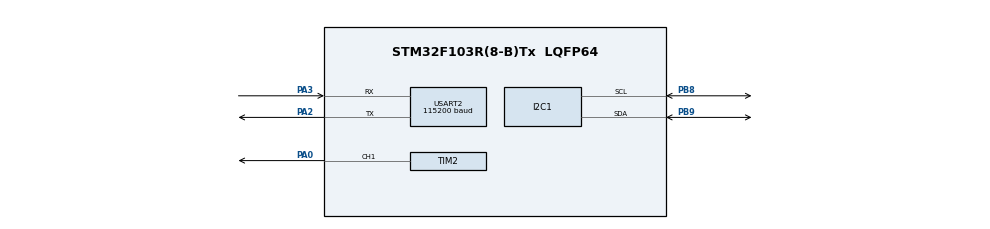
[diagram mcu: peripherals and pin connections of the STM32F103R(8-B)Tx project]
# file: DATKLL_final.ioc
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Dma.Request0=TIM2_CH1
Dma.TIM2_CH1.0.Direction=DMA_MEMORY_TO_PERIPH
Dma.TIM2_CH1.0.Instance=DMA1_Channel5
Dma.TIM2_CH1.0.MemDataAlignment=DMA_MDATAALIGN_HALFWORD
Dma.TIM2_CH1.0.MemInc=DMA_MINC_ENABLE
Dma.TIM2_CH1.0.Mode=DMA_NORMAL
Dma.TIM2_CH1.0.PeriphDataAlignment=DMA_PDATAALIGN_HALFWORD
Dma.TIM2_CH1.0.PeriphInc=DMA_PINC_DISABLE
Dma.TIM2_CH1.0.Priority=DMA_PRIORITY_VERY_HIGH
Mcu.Family=STM32F1
Mcu.Name=STM32F103R(8-B)Tx
Mcu.Package=LQFP64
NVIC.DMA1_Channel5_IRQn=true\:0\:0\:false\:false\:true\:false\:true
NVIC.PriorityGroup=NVIC_PRIORITYGROUP_4
NVIC.RCC_IRQn=true\:0\:0\:false\:false\:true\:true\:false
NVIC.TIM3_IRQn=true\:0\:0\:false\:false\:true\:true\:true
NVIC.USART2_IRQn=true\:0\:0\:false\:false\:true\:true\:true
PA0-WKUP.Signal=S_TIM2_CH1_ETR
PA13.Mode=Serial_Wire
PA13.Signal=SYS_JTMS-SWDIO
PA14.Mode=Serial_Wire
PA14.Signal=SYS_JTCK-SWCLK
PA2.Mode=Asynchronous
PA2.Signal=USART2_TX
PA3.Mode=Asynchronous
PA3.Signal=USART2_RX
PB8.Mode=I2C
PB8.Signal=I2C1_SCL
PB9.Mode=I2C
PB9.Signal=I2C1_SDA
PD0-OSC_IN.Mode=HSE-External-Oscillator
PD0-OSC_IN.Signal=RCC_OSC_IN
PD1-OSC_OUT.Mode=HSE-External-Oscillator
PD1-OSC_OUT.Signal=RCC_OSC_OUT
ProjectManager.HeapSize=0x200
ProjectManager.StackSize=0x400
ProjectManager.TargetToolchain=STM32CubeIDE
RCC.APB1Freq_Value=8000000
RCC.APB2Freq_Value=8000000
SH.S_TIM2_CH1_ETR.0=TIM2_CH1,PWM Generation1 CH1
TIM2.Channel-PWM\ Generation1\ CH1=TIM_CHANNEL_1
TIM2.OCMode_PWM-PWM\ Generation1\ CH1=TIM_OCMODE_PWM1
TIM2.Period=999
TIM2.Prescaler=79
TIM2.Pulse-PWM\ Generation1\ CH1=199
TIM3.Period=9
TIM3.Prescaler=7999
USART2.BaudRate=115200
USART2.VirtualMode=VM_ASYNC
VP_TIM2_VS_ClockSourceINT.Mode=Internal
VP_TIM3_VS_ClockSourceINT.Mode=Internal
board=custom

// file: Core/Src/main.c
/* USER CODE BEGIN Header */
/**
  ******************************************************************************
  * @file           : main.c
  * @brief          : Main program body
  ******************************************************************************
  * @attention
  *
  * <h2><center>&copy; Copyright (c) 2024 STMicroelectronics.
  * All rights reserved.</center></h2>
  *
  * This software component is licensed by ST under BSD 3-Clause license,
  * the "License"; You may not use this file except in compliance with the
  * License. You may obtain a copy of the License at:
  *                        opensource.org/licenses/BSD-3-Clause
  *
  ******************************************************************************
  */
/* USER CODE END Header */
#include "global.h"

I2C_HandleTypeDef hi2c1;

TIM_HandleTypeDef htim2;
TIM_HandleTypeDef htim3;
DMA_HandleTypeDef hdma_tim2_ch1;

UART_HandleTypeDef huart2;

void SystemClock_Config(void);
static void MX_GPIO_Init(void);
static void MX_I2C1_Init(void);
static void MX_TIM2_Init(void);
static void MX_DMA_Init(void);
static void MX_USART2_UART_Init(void);
static void MX_TIM3_Init(void);

int main(void)
{

  /* MCU Configuration--------------------------------------------------------*/

  /* Reset of all peripherals, Initializes the Flash interface and the Systick. */
  HAL_Init();

  /* Configure the system clock */
  SystemClock_Config();

  /* Initialize all configured peripherals */
  MX_GPIO_Init();
  MX_I2C1_Init();
  MX_TIM2_Init();
  MX_DMA_Init();
  MX_USART2_UART_Init();
  MX_TIM3_Init();
  /* USER CODE BEGIN 2 */
  HAL_TIM_Base_Start_IT(&htim2);
  HAL_TIM_Base_Start_IT(&htim3);
  HAL_TIM_PWM_Start(&htim2, TIM_CHANNEL_1);
  lcd_init();
  lcd_clear_display();
  HAL_Delay(1000);

  /* USER CODE END 2 */

  /* Infinite loop */
  /* USER CODE BEGIN WHILE */

  setTimer0(200);
  while (1)
  {
//	  lcd_clear_display();
	  if (timer_flag0 == 1) {
		  fsm_run();
		  setTimer0(1000);
	  }
    /* USER CODE END WHILE */

  }
}

void SystemClock_Config(void)
{
  RCC_OscInitTypeDef RCC_OscInitStruct = {0};
  RCC_ClkInitTypeDef RCC_ClkInitStruct = {0};

  /** Initializes the RCC Oscillators according to the specified parameters
  * in the RCC_OscInitTypeDef structure.
  */
  RCC_OscInitStruct.OscillatorType = RCC_OSCILLATORTYPE_HSI;
  RCC_OscInitStruct.HSIState = RCC_HSI_ON;
  RCC_OscInitStruct.HSICalibrationValue = RCC_HSICALIBRATION_DEFAULT;
  RCC_OscInitStruct.PLL.PLLState = RCC_PLL_NONE;
  if (HAL_RCC_OscConfig(&RCC_OscInitStruct) != HAL_OK)
  {
    Error_Handler();
  }
  /** Initializes the CPU, AHB and APB buses clocks
  */
  RCC_ClkInitStruct.ClockType = RCC_CLOCKTYPE_HCLK|RCC_CLOCKTYPE_SYSCLK
                              |RCC_CLOCKTYPE_PCLK1|RCC_CLOCKTYPE_PCLK2;
  RCC_ClkInitStruct.SYSCLKSource = RCC_SYSCLKSOURCE_HSI;
  RCC_ClkInitStruct.AHBCLKDivider = RCC_SYSCLK_DIV1;
  RCC_ClkInitStruct.APB1CLKDivider = RCC_HCLK_DIV1;
  RCC_ClkInitStruct.APB2CLKDivider = RCC_HCLK_DIV1;

  if (HAL_RCC_ClockConfig(&RCC_ClkInitStruct, FLASH_LATENCY_0) != HAL_OK)
  {
    Error_Handler();
  }
}

static void MX_I2C1_Init(void)
{

  hi2c1.Instance = I2C1;
  hi2c1.Init.ClockSpeed = 100000;
  hi2c1.Init.DutyCycle = I2C_DUTYCYCLE_2;
  hi2c1.Init.OwnAddress1 = 0;
  hi2c1.Init.AddressingMode = I2C_ADDRESSINGMODE_7BIT;
  hi2c1.Init.DualAddressMode = I2C_DUALADDRESS_DISABLE;
  hi2c1.Init.OwnAddress2 = 0;
  hi2c1.Init.GeneralCallMode = I2C_GENERALCALL_DISABLE;
  hi2c1.Init.NoStretchMode = I2C_NOSTRETCH_DISABLE;
  if (HAL_I2C_Init(&hi2c1) != HAL_OK)
  {
    Error_Handler();
  }

}

static void MX_TIM2_Init(void)
{

  TIM_ClockConfigTypeDef sClockSourceConfig = {0};
  TIM_MasterConfigTypeDef sMasterConfig = {0};
  TIM_OC_InitTypeDef sConfigOC = {0};

  htim2.Instance = TIM2;
  htim2.Init.Prescaler = 79;
  htim2.Init.CounterMode = TIM_COUNTERMODE_UP;
  htim2.Init.Period = 999;
  htim2.Init.ClockDivision = TIM_CLOCKDIVISION_DIV1;
  htim2.Init.AutoReloadPreload = TIM_AUTORELOAD_PRELOAD_DISABLE;
  if (HAL_TIM_Base_Init(&htim2) != HAL_OK)
  {
    Error_Handler();
  }
  sClockSourceConfig.ClockSource = TIM_CLOCKSOURCE_INTERNAL;
  if (HAL_TIM_ConfigClockSource(&htim2, &sClockSourceConfig) != HAL_OK)
  {
    Error_Handler();
  }
  if (HAL_TIM_PWM_Init(&htim2) != HAL_OK)
  {
    Error_Handler();
  }
  sMasterConfig.MasterOutputTrigger = TIM_TRGO_RESET;
  sMasterConfig.MasterSlaveMode = TIM_MASTERSLAVEMODE_DISABLE;
  if (HAL_TIMEx_MasterConfigSynchronization(&htim2, &sMasterConfig) != HAL_OK)
  {
    Error_Handler();
  }
  sConfigOC.OCMode = TIM_OCMODE_PWM1;
  sConfigOC.Pulse = 199;
  sConfigOC.OCPolarity = TIM_OCPOLARITY_HIGH;
  sConfigOC.OCFastMode = TIM_OCFAST_DISABLE;
  if (HAL_TIM_PWM_ConfigChannel(&htim2, &sConfigOC, TIM_CHANNEL_1) != HAL_OK)
  {
    Error_Handler();
  }
  HAL_TIM_MspPostInit(&htim2);

}

static void MX_TIM3_Init(void)
{

  TIM_ClockConfigTypeDef sClockSourceConfig = {0};
  TIM_MasterConfigTypeDef sMasterConfig = {0};

  htim3.Instance = TIM3;
  htim3.Init.Prescaler = 7999;
  htim3.Init.CounterMode = TIM_COUNTERMODE_UP;
  htim3.Init.Period = 9;
  htim3.Init.ClockDivision = TIM_CLOCKDIVISION_DIV1;
  htim3.Init.AutoReloadPreload = TIM_AUTORELOAD_PRELOAD_DISABLE;
  if (HAL_TIM_Base_Init(&htim3) != HAL_OK)
  {
    Error_Handler();
  }
  sClockSourceConfig.ClockSource = TIM_CLOCKSOURCE_INTERNAL;
  if (HAL_TIM_ConfigClockSource(&htim3, &sClockSourceConfig) != HAL_OK)
  {
    Error_Handler();
  }
  sMasterConfig.MasterOutputTrigger = TIM_TRGO_RESET;
  sMasterConfig.MasterSlaveMode = TIM_MASTERSLAVEMODE_DISABLE;
  if (HAL_TIMEx_MasterConfigSynchronization(&htim3, &sMasterConfig) != HAL_OK)
  {
    Error_Handler();
  }

}

static void MX_USART2_UART_Init(void)
{

  huart2.Instance = USART2;
  huart2.Init.BaudRate = 115200;
  huart2.Init.WordLength = UART_WORDLENGTH_8B;
  huart2.Init.StopBits = UART_STOPBITS_1;
  huart2.Init.Parity = UART_PARITY_NONE;
  huart2.Init.Mode = UART_MODE_TX_RX;
  huart2.Init.HwFlowCtl = UART_HWCONTROL_NONE;
  huart2.Init.OverSampling = UART_OVERSAMPLING_16;
  if (HAL_UART_Init(&huart2) != HAL_OK)
  {
    Error_Handler();
  }

}

static void MX_DMA_Init(void)
{

  /* DMA controller clock enable */
  __HAL_RCC_DMA1_CLK_ENABLE();

  /* DMA interrupt init */
  /* DMA1_Channel5_IRQn interrupt configuration */
  HAL_NVIC_SetPriority(DMA1_Channel5_IRQn, 0, 0);
  HAL_NVIC_EnableIRQ(DMA1_Channel5_IRQn);

}

static void MX_GPIO_Init(void)
{

  /* GPIO Ports Clock Enable */
  __HAL_RCC_GPIOD_CLK_ENABLE();
  __HAL_RCC_GPIOA_CLK_ENABLE();
  __HAL_RCC_GPIOB_CLK_ENABLE();

}

/* USER CODE BEGIN 4 */
void HAL_TIM_PeriodElapsedCallback(TIM_HandleTypeDef *htim){
//	SCH_Update();
	timer_run();
}
/* USER CODE END 4 */

void Error_Handler(void)
{
  __disable_irq();
  while (1)
  {
  }
}

/************************ (C) COPYRIGHT STMicroelectronics *****END OF FILE****/
